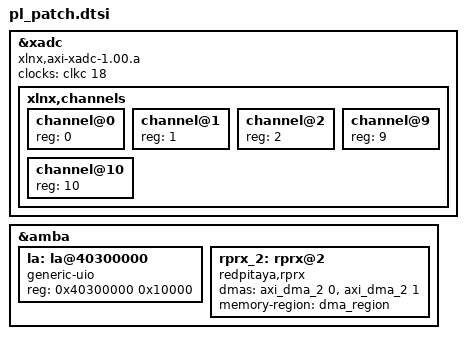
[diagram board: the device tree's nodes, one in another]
/*
 * Zynq XADC configuration
*/

&xadc {
        compatible = "xlnx,axi-xadc-1.00.a";
        clocks = <&clkc 18>;
        xlnx,channels {
                #address-cells = <1>;
                #size-cells = <0>;
                channel@0 {
                        reg = <0>;
                };
                channel@1 {
                        reg = <1>;
                };
                channel@2 {
                        reg = <2>;
                };
                channel@9 {
                        reg = <9>;
                };
                channel@10 {
                        reg = <10>;
                };
        };
};

&amba {
        la: la@40300000 {
            compatible = "generic-uio";
            reg = <0x40300000 0x10000>;
        };

        rprx_2: rprx@2 {
                compatible ="redpitaya,rprx";
                dmas = <&axi_dma_2 0
                                &axi_dma_2 1>;
                dma-names = "axidma0", "axidma1";
                memory-region = <&dma_region>;
        };
};
